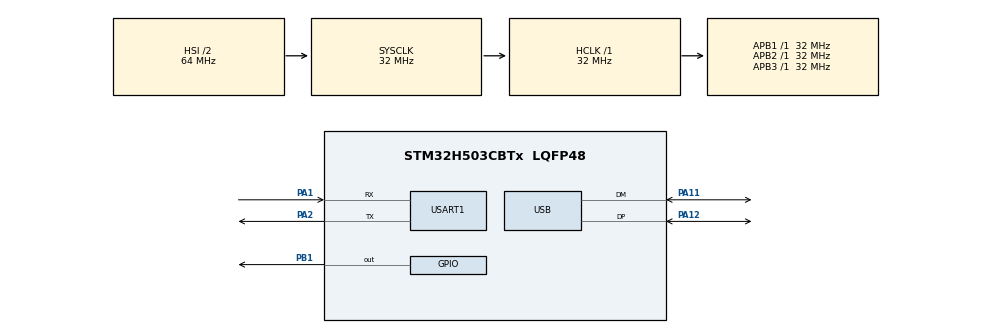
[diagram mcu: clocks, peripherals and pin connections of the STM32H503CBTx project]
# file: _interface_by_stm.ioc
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Mcu.Family=STM32H5
Mcu.Name=STM32H503CBTx
Mcu.Package=LQFP48
NVIC.PriorityGroup=NVIC_PRIORITYGROUP_4
NVIC.USART1_IRQn=true\:0\:0\:false\:false\:true\:true\:true\:true
PA1.Mode=Asynchronous
PA1.Signal=USART1_RX
PA11.Mode=Device
PA11.Signal=USB_DM
PA12.Mode=Device
PA12.Signal=USB_DP
PA2.Mode=Asynchronous
PA2.Signal=USART1_TX
PB1.Signal=GPIO_Output
ProjectManager.HeapSize=0x200
ProjectManager.StackSize=0x400
ProjectManager.TargetToolchain=STM32CubeIDE
RCC.ADCFreq_Value=32000000
RCC.AHBFreq_Value=32000000
RCC.APB1Freq_Value=32000000
RCC.APB1TimFreq_Value=32000000
RCC.APB2Freq_Value=32000000
RCC.APB2TimFreq_Value=32000000
RCC.APB3Freq_Value=32000000
RCC.CSI_VALUE=4000000
RCC.CortexFreq_Value=32000000
RCC.EPOD_VALUE=4000000
RCC.HCLKFreq_Value=32000000
RCC.HSE_VALUE=25000000
RCC.HSI48_VALUE=48000000
RCC.HSI_VALUE=64000000
RCC.LSE_VALUE=32768
RCC.LSIRC_VALUE=32000
RCC.SYSCLKFreq_VALUE=32000000
RCC.USBFreq_Value=48000000
RCC.VCOOutputFreq_Value=516000000
USART1.VirtualMode-Asynchronous=VM_ASYNC
USB.VirtualMode=Device_Only
VP_BOOTPATH_VS_BOOTPATH.Mode=BP_Activate
VP_CORTEX_M33_NS_VS_Hclk.Mode=Hclk_Mode
VP_MEMORYMAP_VS_MEMORYMAP.Mode=CurAppReg
VP_PWR_VS_LPOM.Mode=PowerOptimisation
VP_PWR_VS_SECSignals.Mode=Security/Privilege
board=custom

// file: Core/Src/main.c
/* USER CODE BEGIN Header */
/**
  ******************************************************************************
  * @file           : main.c
  * @brief          : Main program body
  ******************************************************************************
  * @attention
  *
  * Copyright (c) 2025 STMicroelectronics.
  * All rights reserved.
  *
  * This software is licensed under terms that can be found in the LICENSE file
  * in the root directory of this software component.
  * If no LICENSE file comes with this software, it is provided AS-IS.
  *
  ******************************************************************************
  */
/* USER CODE END Header */
#include "main.h"

UART_HandleTypeDef huart1;

PCD_HandleTypeDef hpcd_USB_DRD_FS;

void SystemClock_Config(void);
static void MX_GPIO_Init(void);
static void MX_USART1_UART_Init(void);
static void MX_USB_PCD_Init(void);

/* USER CODE BEGIN 0 */
uint8_t buff[1];
volatile uint8_t flag = 0;
void HAL_UART_RxCpltCallback ( UART_HandleTypeDef *huart ) {
	  if ( huart->Instance == USART1 ){
		  if ( buff[0] == '1' ){
			  flag = 1;
		  }
		  else if (buff[0] == '2'){
			  flag = 0;
		  }
	  }
	  HAL_UART_Receive_IT(&huart1, buff, sizeof(buff));
  }
/* USER CODE END 0 */

int main(void)
{

  /* MCU Configuration--------------------------------------------------------*/

  /* Reset of all peripherals, Initializes the Flash interface and the Systick. */
  HAL_Init();

  /* Configure the system clock */
  SystemClock_Config();

  /* Initialize all configured peripherals */
  MX_GPIO_Init();
  MX_USART1_UART_Init();
  MX_USB_PCD_Init();

  /* Infinite loop */
  /* USER CODE BEGIN WHILE */

  HAL_UART_Receive_IT(&huart1, buff, sizeof(buff));
  while (1)
  {
    /* USER CODE END WHILE */
	 if (flag == 1){
		 HAL_GPIO_WritePin(GPIOB, GPIO_PIN_1, GPIO_PIN_SET);

	 }
	 else if (flag == 0){
		 HAL_GPIO_WritePin(GPIOB, GPIO_PIN_1, GPIO_PIN_RESET);

	 }
  }
}

void SystemClock_Config(void)
{
  RCC_OscInitTypeDef RCC_OscInitStruct = {0};
  RCC_ClkInitTypeDef RCC_ClkInitStruct = {0};

  /** Configure the main internal regulator output voltage
  */
  __HAL_PWR_VOLTAGESCALING_CONFIG(PWR_REGULATOR_VOLTAGE_SCALE3);

  while(!__HAL_PWR_GET_FLAG(PWR_FLAG_VOSRDY)) {}

  /** Initializes the RCC Oscillators according to the specified parameters
  * in the RCC_OscInitTypeDef structure.
  */
  RCC_OscInitStruct.OscillatorType = RCC_OSCILLATORTYPE_HSI48|RCC_OSCILLATORTYPE_HSI;
  RCC_OscInitStruct.HSIState = RCC_HSI_ON;
  RCC_OscInitStruct.HSIDiv = RCC_HSI_DIV2;
  RCC_OscInitStruct.HSICalibrationValue = RCC_HSICALIBRATION_DEFAULT;
  RCC_OscInitStruct.HSI48State = RCC_HSI48_ON;
  RCC_OscInitStruct.PLL.PLLState = RCC_PLL_NONE;
  if (HAL_RCC_OscConfig(&RCC_OscInitStruct) != HAL_OK)
  {
    Error_Handler();
  }

  /** Initializes the CPU, AHB and APB buses clocks
  */
  RCC_ClkInitStruct.ClockType = RCC_CLOCKTYPE_HCLK|RCC_CLOCKTYPE_SYSCLK
                              |RCC_CLOCKTYPE_PCLK1|RCC_CLOCKTYPE_PCLK2
                              |RCC_CLOCKTYPE_PCLK3;
  RCC_ClkInitStruct.SYSCLKSource = RCC_SYSCLKSOURCE_HSI;
  RCC_ClkInitStruct.AHBCLKDivider = RCC_SYSCLK_DIV1;
  RCC_ClkInitStruct.APB1CLKDivider = RCC_HCLK_DIV1;
  RCC_ClkInitStruct.APB2CLKDivider = RCC_HCLK_DIV1;
  RCC_ClkInitStruct.APB3CLKDivider = RCC_HCLK_DIV1;

  if (HAL_RCC_ClockConfig(&RCC_ClkInitStruct, FLASH_LATENCY_1) != HAL_OK)
  {
    Error_Handler();
  }

  /** Configure the programming delay
  */
  __HAL_FLASH_SET_PROGRAM_DELAY(FLASH_PROGRAMMING_DELAY_0);
}

static void MX_USART1_UART_Init(void)
{

  huart1.Instance = USART1;
  huart1.Init.BaudRate = 115200;
  huart1.Init.WordLength = UART_WORDLENGTH_8B;
  huart1.Init.StopBits = UART_STOPBITS_1;
  huart1.Init.Parity = UART_PARITY_NONE;
  huart1.Init.Mode = UART_MODE_TX_RX;
  huart1.Init.HwFlowCtl = UART_HWCONTROL_NONE;
  huart1.Init.OverSampling = UART_OVERSAMPLING_16;
  huart1.Init.OneBitSampling = UART_ONE_BIT_SAMPLE_DISABLE;
  huart1.Init.ClockPrescaler = UART_PRESCALER_DIV1;
  huart1.AdvancedInit.AdvFeatureInit = UART_ADVFEATURE_NO_INIT;
  if (HAL_UART_Init(&huart1) != HAL_OK)
  {
    Error_Handler();
  }
  if (HAL_UARTEx_SetTxFifoThreshold(&huart1, UART_TXFIFO_THRESHOLD_1_8) != HAL_OK)
  {
    Error_Handler();
  }
  if (HAL_UARTEx_SetRxFifoThreshold(&huart1, UART_RXFIFO_THRESHOLD_1_8) != HAL_OK)
  {
    Error_Handler();
  }
  if (HAL_UARTEx_DisableFifoMode(&huart1) != HAL_OK)
  {
    Error_Handler();
  }

}

static void MX_USB_PCD_Init(void)
{

  hpcd_USB_DRD_FS.Instance = USB_DRD_FS;
  hpcd_USB_DRD_FS.Init.dev_endpoints = 8;
  hpcd_USB_DRD_FS.Init.speed = USBD_FS_SPEED;
  hpcd_USB_DRD_FS.Init.phy_itface = PCD_PHY_EMBEDDED;
  hpcd_USB_DRD_FS.Init.Sof_enable = DISABLE;
  hpcd_USB_DRD_FS.Init.low_power_enable = DISABLE;
  hpcd_USB_DRD_FS.Init.lpm_enable = DISABLE;
  hpcd_USB_DRD_FS.Init.battery_charging_enable = DISABLE;
  hpcd_USB_DRD_FS.Init.vbus_sensing_enable = DISABLE;
  hpcd_USB_DRD_FS.Init.bulk_doublebuffer_enable = DISABLE;
  hpcd_USB_DRD_FS.Init.iso_singlebuffer_enable = DISABLE;
  if (HAL_PCD_Init(&hpcd_USB_DRD_FS) != HAL_OK)
  {
    Error_Handler();
  }

}

static void MX_GPIO_Init(void)
{
  GPIO_InitTypeDef GPIO_InitStruct = {0};

  /* GPIO Ports Clock Enable */
  __HAL_RCC_GPIOA_CLK_ENABLE();
  __HAL_RCC_GPIOB_CLK_ENABLE();

  /*Configure GPIO pin Output Level */
  HAL_GPIO_WritePin(GPIOB, GPIO_PIN_1, GPIO_PIN_RESET);

  /*Configure GPIO pin : PB1 */
  GPIO_InitStruct.Pin = GPIO_PIN_1;
  GPIO_InitStruct.Mode = GPIO_MODE_OUTPUT_PP;
  GPIO_InitStruct.Pull = GPIO_NOPULL;
  GPIO_InitStruct.Speed = GPIO_SPEED_FREQ_LOW;
  HAL_GPIO_Init(GPIOB, &GPIO_InitStruct);

}

void Error_Handler(void)
{
  __disable_irq();
  while (1)
  {
  }
}
